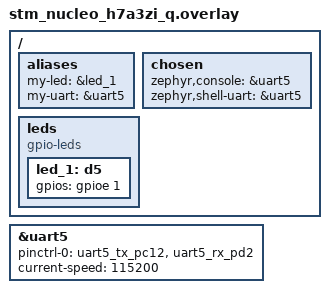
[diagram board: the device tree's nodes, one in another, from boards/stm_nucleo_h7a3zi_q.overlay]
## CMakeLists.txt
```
# SPDX-License-Identifier: Apache-2.0

cmake_minimum_required(VERSION 3.20.0)
find_package(Zephyr REQUIRED HINTS $ENV{ZEPHYR_BASE})
project(blinky)
target_sources(app PRIVATE src/main.c src/add.c)
target_include_directories(app PUBLIC ${CMAKE_CURRENT_SOURCE_DIR}/lib)
```

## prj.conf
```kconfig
CONFIG_GPIO=y
CONFIG_USB_DEVICE_STACK=y
CONFIG_USB_CDC_ACM=y
CONFIG_UART_LINE_CTRL=y
CONFIG_SERIAL=y
CONFIG_UART_CONSOLE=y
CONFIG_UART_LINE_CTRL=y
CONFIG_LOG_BACKEND_UART=y
CONFIG_UART_INTERRUPT_DRIVEN=y
```

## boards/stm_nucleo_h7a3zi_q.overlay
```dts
/{
        aliases{
          my-led=&led_1;
          my-uart=&uart5;
        };
        chosen {
          zephyr,console=&uart5;
          zephyr,shell-uart = &uart5;
        };
        leds: leds {
          compatible="gpio-leds";
          led_1:d5{
            gpios=<&gpioe 1  GPIO_ACTIVE_HIGH>;

          };
        };

};

&uart5{
	pinctrl-0 = <&uart5_tx_pc12 &uart5_rx_pd2>;
	pinctrl-names = "default";
	status = "okay";
	current-speed = <115200>;
};
```

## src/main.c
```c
/*
 * Copyright (c) 2016 Intel Corporation
 *
 * SPDX-License-Identifier: Apache-2.0
 */

#include <stdio.h>
#include <zephyr/kernel.h>
#include <zephyr/drivers/gpio.h>
#include<zephyr/drivers/uart.h>
#include "add.h"
/* 1000 msec = 1 sec */
#define SLEEP_TIME_MS   1000

/* The devicetree node identifier for the "led0" alias. */


/*
 * A build error on this line means your board is unsupported.
 * See the sample documentation for information on how to fix this.
 */
static const struct gpio_dt_spec led = GPIO_DT_SPEC_GET(DT_ALIAS(my_led), gpios);
static const struct device *my_usart=DEVICE_DT_GET(DT_ALIAS(my_uart));

int main(void)
{
	int ret;
	bool led_state = true;

	if (!gpio_is_ready_dt(&led)) {
		return 0;
	}
  if (!device_is_ready(my_usart)) {
    printk("UART not ready!\n");
    return 0;
  }

	ret = gpio_pin_configure_dt(&led, GPIO_OUTPUT_ACTIVE);
	gpio_pin_set_dt(&led , 1);
	if (ret < 0) {
		return 0;
	}
  unsigned char test='a';
  unsigned char c;
  while (1) {
		if (ret < 0) {
			return 0;
		}

		led_state = !led_state;
    uart_poll_out(my_usart,test);
    int err = uart_poll_in(my_usart,&c);
    if(err==0){
      if(c=='a'){
        gpio_pin_toggle_dt(&led);
      }
    }
    
		add();
		k_msleep(SLEEP_TIME_MS);
	}
	return 0;
}
```

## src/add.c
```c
#include<zephyr/kernel.h>
#include<zephyr/sys/printk.h>
#include "add.h"

void add(){
  int result =5+3;
  printk("%d",result);
}
```
